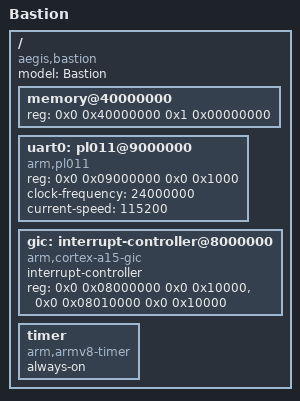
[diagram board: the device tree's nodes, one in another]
/* Bastion Device Tree Source (QEMU virt-compatible) */
/dts-v1/;

/ {
    compatible = "aegis,bastion";
    model = "Bastion";
    #address-cells = <2>;
    #size-cells = <2>;

    memory@40000000 {
        device_type = "memory";
        reg = <0x0 0x40000000 0x1 0x00000000>;
    };

    uart0: pl011@9000000 {
        compatible = "arm,pl011", "arm,primecell";
        reg = <0x0 0x09000000 0x0 0x1000>;
        clock-frequency = <24000000>;
        current-speed = <115200>;
        status = "okay";
    };

    gic: interrupt-controller@8000000 {
        compatible = "arm,cortex-a15-gic";
        #interrupt-cells = <3>;
        interrupt-controller;
        reg = <0x0 0x08000000 0x0 0x10000>,
              <0x0 0x08010000 0x0 0x10000>;
    };

    timer {
        compatible = "arm,armv8-timer";
        always-on;
    };
};
